VERSION "1.0"

NS_ :

BU_:
    BCM
    DIM
    FLCM
    RLCM
    GWM
    PAM
    TCU
    HVAC

BA_DEF_ BO_ "GenMsgCycleTime" FLOAT 0 10000;
BA_DEF_ SG_ "GenSigStartValue" FLOAT 0 0;

BO_ 100 DaylightRunningLightControl: 1 BCM
  SG_ LeftDaylightRunningLightRequest : 0|1@1+ (1,0) [0|1] ""  DIM, FLCM, RLCM
  SG_ RightDaylightRunningLightRequest : 1|1@1+ (1,0) [0|1] ""  DIM, FLCM, RLCM

BO_ 101 LowBeamLightControl: 1 BCM
  SG_ LeftLowBeamLightRequest : 0|1@1+ (1,0) [0|1] ""  DIM, FLCM, RLCM
  SG_ RightLowBeamLightRequest : 1|1@1+ (1,0) [0|1] ""  DIM, FLCM, RLCM

BO_ 102 HighBeamLightControl: 1 BCM
  SG_ LeftHighBeamLightRequest : 0|1@1+ (1,0) [0|1] ""  DIM, FLCM
  SG_ RightHighBeamLightRequest : 1|1@1+ (1,0) [0|1] ""  DIM, FLCM

BO_ 103 TurnLightControl: 1 BCM
  SG_ LeftTurnLightRequest : 0|1@1+ (1,0) [0|1] ""  DIM, FLCM, RLCM, GWM
  SG_ RightTurnLightRequest : 1|1@1+ (1,0) [0|1] ""  DIM, FLCM, RLCM, GWM

BO_ 104 BrakeLightControl: 1 BCM
  SG_ LeftBrakeLightRequest : 0|1@1+ (1,0) [0|1] ""  DIM, RLCM, GWM
  SG_ RightBrakeLightRequest : 1|1@1+ (1,0) [0|1] ""  DIM, RLCM, GWM

BO_ 106 SteeringWheelInfo: 8 BCM
  SG_ SteeringWheelPosition : 0|14@1+ (0.1,-819.2) [-819.2|819.1] "deg"  DIM, GWM

BO_ 107 AcceleratorPedalInfo: 8 BCM
  SG_ AcceleratorPedalPosition : 0|8@1+ (1,0) [0|255] ""  DIM, GWM

BO_ 108 GearInfo: 1 BCM
  SG_ GearLeverPosition : 0|1@1+ (1,0) [0|1] "" DIM, GWM

BO_ 109 ProximityInfo: 2 PAM
  SG_ ProximityDistance : 0|8@1+ (0.02,0) [0|5.10] "m"  DIM, GWM

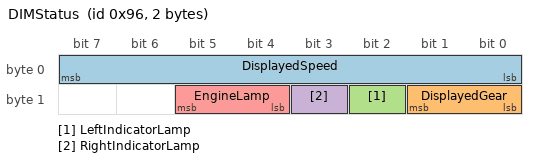
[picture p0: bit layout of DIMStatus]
BO_ 150 DIMStatus: 2 DIM
  SG_ DisplayedSpeed : 0|8@1+ (1,0) [0|255] "km/h" GWM
  SG_ DisplayedGear : 8|2@1+ (1,0) [0|3] "" GWM
  SG_ LeftIndicatorLamp : 10|1@1+ (1,0) [0|1] "" GWM
  SG_ RightIndicatorLamp : 11|1@1+ (1,0) [0|1] "" GWM
  SG_ EngineLamp : 12|2@1+ (1,0) [0|3] "" GWM

BO_ 200 LocationFrame: 12 TCU
 SG_ Longitude : 28|28@1- (1E-006,0) [-134.218|134.218] "Deg"  GWM
 SG_ Latitude : 0|28@1- (1E-006,0) [-134.218|134.218] "Deg"  GWM
 SG_ Heading : 56|28@1+ (1E-005,0) [0|360] "Deg"  GWM

BO_ 300 HVACControl: 8 GWM
 SG_ LeftTemperature : 0|16@1+ (0.1,0) [16|30] "°C" HVAC
 SG_ RightTemperature : 16|16@1+ (0.1,0) [16|30] "°C" HVAC

VAL_ 100 LeftDaylightRunningLightRequest 0 "Off" 1 "On";
VAL_ 100 RightDaylightRunningLightRequest 0 "Off" 1 "On";
VAL_ 101 LeftLowBeamLightRequest 0 "Off" 1 "On";
VAL_ 101 RightLowBeamLightRequest 0 "Off" 1 "On";
VAL_ 102 LeftHighBeamLightRequest 0 "Off" 1 "On";
VAL_ 102 RightHighBeamLightRequest 0 "Off" 1 "On";
VAL_ 103 LeftTurnLightRequest 0 "Off" 1 "On";
VAL_ 103 RightTurnLightRequest 0 "Off" 1 "On";
VAL_ 104 LeftBrakeLightRequest 0 "Off" 1 "On";
VAL_ 104 RightBrakeLightRequest 0 "Off" 1 "On";
VAL_ 108 GearLeverPosition 0 "Reverse" 1 "Drive";
VAL_ 109 ProximityDistance 255 "NoObject";
VAL_ 150 DisplayedSpeed 255 "NotDisplayed";
VAL_ 150 DisplayedGear 0 "NotDisplayed" 1 "Reverse" 2 "Drive";
VAL_ 150 LeftIndicatorLamp 0 "Off" 1 "On";
VAL_ 150 RightIndicatorLamp 0 "Off" 1 "On";
VAL_ 150 EngineLamp 0 "Off" 1 "SNA" 2 "Error";

BA_ "GenSigStartValue" SG_ 100 LeftDaylightRunningLightRequest 0;
BA_ "GenSigStartValue" SG_ 100 RightDaylightRunningLightRequest 0;
BA_ "GenSigStartValue" SG_ 101 LeftLowBeamLightRequest 0;
BA_ "GenSigStartValue" SG_ 101 RightLowBeamLightRequest 0;
BA_ "GenSigStartValue" SG_ 102 LeftHighBeamLightRequest 0;
BA_ "GenSigStartValue" SG_ 102 RightHighBeamLightRequest 0;
BA_ "GenSigStartValue" SG_ 103 LeftTurnLightRequest 0;
BA_ "GenSigStartValue" SG_ 103 RightTurnLightRequest 0;
BA_ "GenSigStartValue" SG_ 104 LeftBrakeLightRequest 0;
BA_ "GenSigStartValue" SG_ 104 RightBrakeLightRequest 0;
BA_ "GenSigStartValue" SG_ 106 SteeringWheelPosition 0;
BA_ "GenSigStartValue" SG_ 107 AcceleratorPedalPosition 0;
BA_ "GenSigStartValue" SG_ 108 GearLeverPosition 1;
BA_ "GenSigStartValue" SG_ 109 ProximityDistance 255;
BA_ "GenSigStartValue" SG_ 110 VehicleSpeed 0;
BA_ "GenSigStartValue" SG_ 150 DisplayedSpeed 255;
BA_ "GenSigStartValue" SG_ 150 DisplayedGear 0;
BA_ "GenSigStartValue" SG_ 150 EngineLamp 0;

BA_ "GenMsgCycleTime" BO_ 100 50;
BA_ "GenMsgCycleTime" BO_ 101 50;
BA_ "GenMsgCycleTime" BO_ 102 50;
BA_ "GenMsgCycleTime" BO_ 103 50;
BA_ "GenMsgCycleTime" BO_ 104 50;
BA_ "GenMsgCycleTime" BO_ 106 50;
BA_ "GenMsgCycleTime" BO_ 107 50;
BA_ "GenMsgCycleTime" BO_ 108 50;
BA_ "GenMsgCycleTime" BO_ 109 50;
BA_ "GenMsgCycleTime" BO_ 110 50;
BA_ "GenMsgCycleTime" BO_ 150 100;
BA_ "GenMsgCycleTime" BO_ 200 200;
BA_ "GenMsgCycleTime" BO_ 300 500;
